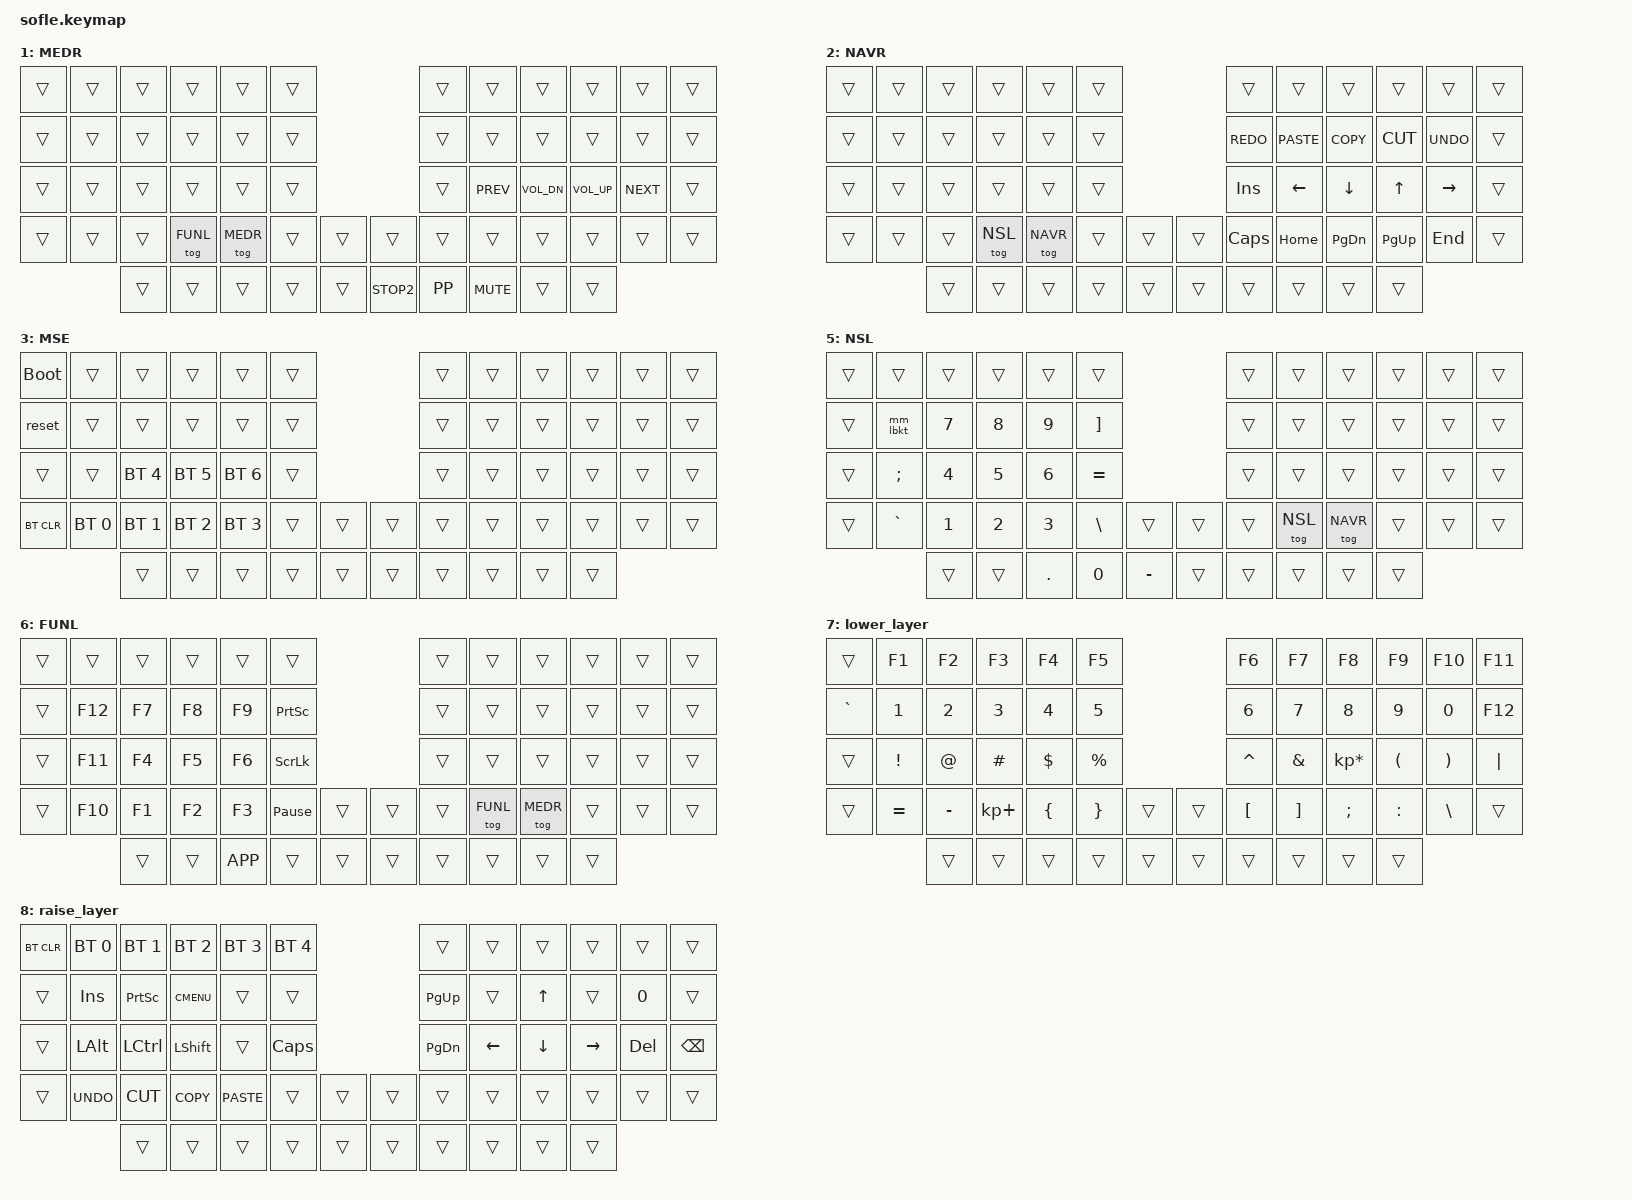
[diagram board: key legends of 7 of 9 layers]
/*
 * Copyright (c) 2020 The ZMK Contributors
 *
 * SPDX-License-Identifier: MIT
 * vim: filetype=dts:ts=4:sw=4:et
 */

#include <behaviors.dtsi>
#include <dt-bindings/zmk/keys.h>
#include <dt-bindings/zmk/bt.h>

#define MEDR 1
#define NAVR 2
#define MSE  3
#define NSSL 4
#define NSL  5
#define FUNL 6
// &mt LSHFT A

#define MACRO_COMBO(NAME, KEYPOS, LAYERS) \
  combo_##NAME { \
    bindings = <&m_##NAME>; \
    key-positions = <KEYPOS>; \
    layers = <LAYERS>; \
    timeout-ms = <50>; \
};

/ {
    #include "hd_combo_macros.dtsi"
    #include "linger.dtsi"

    behaviour {
        hm: homerow_mods {
            compatible = "zmk,behavior-hold-tap";
            label = "HOMEROW_MODS";
            #binding-cells = <2>;
            tapping-term-ms = <175>;
            quick-tap-ms = <125>;
            global-quick-tap;
            flavor = "tap-preferred";
            bindings = <&kp>, <&kp>;
        };
    };

    keymap {
        compatible = "zmk,keymap";

        default_layer {
//    ----------------------------------------------------------------------------------------------
//  0 |  `  |  1  |  2  |  3  |  4  |  5  |  5               6 |  6  |  7  |  8  |  9  |  0  |     | 11
// 12 | ESC |  Q  |  W  |  F  |  P  |  B  | 17              18 |  J  |  L  |  U  |  Y  |  '  |BKSPC| 23
// 24 | TAB |  A  |  R  |  S  |  T  |  G  | 29              30 |  M  |  N  |  E  |  I  |  O  |  '  | 35
// 36 |SHIFT|  Z  |  X  |  C  |  D  |  V  | MUTE| 42  43 |     |  K  |  H  |  ,  |  .  |  /  |SHIFT| 49
//             50 | GUI | ALT | CTRL|LOWER|ENTER| 54  55 |SPACE|RAISE| CTRL| ALT | GUI | 59
            bindings = <
&kp GRAVE &kp N1      &kp N2      &kp N3      &kp N4      &kp N5                      &kp N6 &kp N7      &kp N8      &kp N9      &kp N0      &none
&kp ESC   &qu Q &m_qu &kp W       &kp F       &kp P       &kp B                       &kp J  &kp L       &kp U       &kp Y       &kp APOS    &kp BSPC
&kp TAB   &hm LALT A  &hm LGUI R  &hm LSHFT S &hm LCTRL T &kp G                       &kp M  &hm RCTRL N &hm RSHFT E &hm RGUI I  &hm LALT O  &kp SQT
&kp LSHFT &kp Z       &kp X       &kp C       &kp D       &kp V  &kp C_MUTE &none     &kp K  &kp H       &mm_comma   &mm_dot     &kp FSLH    &kp RSHFT
                 &kp LGUI &kp LALT &lt MEDR ESC  &lt NAVR SPACE &lt MSE TAB    &lt NSSL RET  &lt NSL BSPC &lt FUNL DEL  &kp RALT  &kp RGUI
            >;

            sensor-bindings = <&inc_dec_kp C_VOL_UP C_VOL_DN &inc_dec_kp PG_UP PG_DN>;
        };

        MEDR {
            bindings = <
&trans &trans &trans &trans    &trans    &trans                    &trans   &trans     &trans       &trans       &trans     &trans
&trans &trans &trans &trans    &trans    &trans                    &trans   &trans     &trans       &trans       &trans     &trans
&trans &trans &trans &trans    &trans    &trans                    &trans   &kp K_PREV &kp K_VOL_DN &kp K_VOL_UP &kp K_NEXT &trans
&trans &trans &trans &tog FUNL &tog MEDR &trans &trans &trans      &trans   &trans     &trans       &trans       &trans     &trans
              &trans &trans    &trans    &trans &trans &kp K_STOP2 &kp K_PP &kp K_MUTE &trans       &trans
            >;
        };

        NAVR {
            bindings = <
&trans &trans &trans &trans   &trans    &trans               &trans     &trans      &trans     &trans    &trans     &trans
&trans &trans &trans &trans   &trans    &trans               &kp K_REDO &kp K_PASTE &kp K_COPY &kp K_CUT &kp K_UNDO &trans
&trans &trans &trans &trans   &trans    &trans               &kp INS    &kp LEFT    &kp DOWN   &kp UP    &kp RIGHT  &trans
&trans &trans &trans &tog NSL &tog NAVR &trans &trans &trans &kp CAPS   &kp HOME    &kp PG_DN  &kp PG_UP &kp END    &trans
              &trans &trans   &trans    &trans &trans &trans &trans     &trans      &trans     &trans
            >;
        };

        MSE {
            bindings = <
&bootloader &trans       &trans       &trans       &trans       &trans               &trans &trans &trans &trans &trans &trans
&reset      &trans       &trans       &trans       &trans       &trans               &trans &trans &trans &trans &trans &trans
&trans      &trans       &bt BT_SEL 4 &bt BT_SEL 5 &bt BT_SEL 6 &trans               &trans &trans &trans &trans &trans &trans
&bt BT_CLR  &bt BT_SEL 0 &bt BT_SEL 1 &bt BT_SEL 2 &bt BT_SEL 3 &trans &trans &trans &trans &trans &trans &trans &trans &trans
                        &trans        &trans      &trans        &trans &trans &trans &trans &trans &trans &trans
            >;
        };

        NSSL {
            bindings = <
&trans &trans    &trans   &trans    &trans          &trans                      &trans &trans    &trans &trans &trans &trans
&trans &kp LBRC  &kp AMPS &kp STAR  &kp NON_US_BSLH &kp RBRC                    &trans &trans    &trans &trans &trans &trans
&trans &kp COLON &kp DLLR &kp PRCNT &kp CARET        &kp PLUS                   &trans &trans    &trans &trans &trans &trans
&trans &kp TILDE &kp EXCL &kp AT    &kp HASH         &kp PIPE  &trans    &trans &trans &tog NSSL &trans &trans &trans &trans
                 &trans   &trans    &par &m_par LPAR &kp RPAR  &kp UNDER &trans &trans &trans &trans &trans
            >;
        };

        NSL {
            bindings = <
&trans &trans    &trans &trans &trans  &trans                     &trans &trans    &trans    &trans &trans &trans
&trans &mm_lbkt  &kp N7 &kp N8 &kp N9  &kp RBKT                   &trans &trans    &trans    &trans &trans &trans
&trans &kp SEMI  &kp N4 &kp N5 &kp N6  &kp EQUAL                  &trans &trans    &trans    &trans &trans &trans
&trans &kp GRAVE &kp N1 &kp N2 &kp N3  &kp BSLH  &trans    &trans &trans &tog NSL  &tog NAVR &trans &trans &trans
                 &trans &trans &kp DOT &kp N0    &kp MINUS &trans &trans &trans    &trans    &trans
            >;
        };

        FUNL {
            bindings = <
&trans &trans  &trans &trans &trans    &trans                        &trans &trans    &trans    &trans &trans &trans
&trans &kp F12 &kp F7 &kp F8 &kp F9    &kp PSCRN                     &trans &trans    &trans    &trans &trans &trans
&trans &kp F11 &kp F4 &kp F5 &kp F6    &kp SLCK                      &trans &trans    &trans    &trans &trans &trans
&trans &kp F10 &kp F1 &kp F2 &kp F3    &kp PAUSE_BREAK &trans &trans &trans &tog FUNL &tog MEDR &trans &trans &trans
               &trans &trans &kp K_APP &trans          &trans &trans &trans &trans    &trans    &trans
            >;
        };

        lower_layer {
// TODO: Some binds are waiting for shifted keycode support.
// ------------------------------------------------------------------------------------------------------------
// |       |  F1 |  F2 |  F3  |  F4  |  F5  |                   |  F6  |  F7   |  F8   |  F9  |  F10  |  F11  |
// | `     |   1 |   2 |   3  |   4  |   5  |                   |   6  |   7   |   8   |   9  |    0  |  F12  |
// |       |  !  |  @  |  #   |  $   |  %   |                   |  ^   |  &    |  *    |  (   |   )   |   |   |
// |       |  =  |  -  |  +   |  {   |  }   |        |  |       |  [   |  ]    |  ;    |  :   |   \   |       |
//               |     |      |      |      |        |  |       |      |       |       |      |
            bindings = <
&trans    &kp F1    &kp F2    &kp F3      &kp F4    &kp F5                    &kp F6    &kp F7   &kp F8          &kp F9    &kp F10   &kp F11
&kp GRAVE &kp N1    &kp N2    &kp N3      &kp N4    &kp N5                    &kp N6    &kp N7   &kp N8          &kp N9    &kp N0    &kp F12
&trans    &kp EXCL  &kp AT    &kp HASH    &kp DLLR  &kp PRCNT                 &kp CARET &kp AMPS &kp KP_MULTIPLY &kp LPAR  &kp RPAR  &kp PIPE
&trans    &kp EQUAL &kp MINUS &kp KP_PLUS &kp LBRC  &kp RBRC  &trans   &trans &kp LBKT  &kp RBKT &kp SEMI        &kp COLON &kp BSLH  &trans
                    &trans    &trans      &trans    &trans    &trans   &trans &trans    &trans   &trans          &trans
            >;

            sensor-bindings = <&inc_dec_kp C_VOL_UP C_VOL_DN &inc_dec_kp PG_UP PG_DN>;
        };

        raise_layer {
// ------------------------------------------------------------------------------------------------------------
// |BTCLR| BT1  | BT2  |  BT3  |  BT4  |  BT5 |                |      |      |       |      |       |       |
// |     | INS  | PSCR | GUI   |       |      |                | PGUP |      |   ^   |      |       |       |
// |     | ALT  | CTRL | SHIFT |       | CAPS |                | PGDN |   <- |   v   |  ->  |  DEL  | BKSPC |
// |     | UNDO | CUT  | COPY  | PASTE |      |      |  |      |      |      |       |      |       |       |
//              |      |       |       |      |      |  |      |      |      |       |      |
            bindings = <
&bt BT_CLR &bt BT_SEL 0 &bt BT_SEL 1 &bt BT_SEL 2 &bt BT_SEL 3 &bt BT_SEL 4             &trans    &trans    &trans   &trans    &trans  &trans
&trans     &kp INS      &kp PSCRN    &kp K_CMENU  &trans       &trans                   &kp PG_UP &trans    &kp UP   &trans    &kp N0  &trans
&trans     &kp LALT     &kp LCTRL    &kp LSHFT    &trans       &kp CLCK                 &kp PG_DN &kp LEFT  &kp DOWN &kp RIGHT &kp DEL &kp BSPC
&trans     &kp K_UNDO   &kp K_CUT    &kp K_COPY   &kp K_PASTE  &trans  &trans   &trans  &trans    &trans    &trans   &trans    &trans  &trans
                        &trans       &trans       &trans       &trans  &trans   &trans  &trans    &trans    &trans   &trans
            >;

            sensor-bindings = <&inc_dec_kp C_VOL_UP C_VOL_DN &inc_dec_kp PG_UP PG_DN>;
        };
    };

    combos {
        compatible = "zmk,combos";

        MACRO_COMBO(im, 33 30, 0) // "I'm "
        MACRO_COMBO(id, 33 40, 0) // "I'd "
        MACRO_COMBO(ill, 33 19, 0) // "I'll "
        MACRO_COMBO(ive, 33 41, 0) // "I've "
        MACRO_COMBO(wed, 14 40, 0) // "we'd "
        MACRO_COMBO(well, 14 19, 0) // "we'll "
        MACRO_COMBO(weve, 14 41, 0) // "we've "
        MACRO_COMBO(were, 14 26, 0) // "we're "
        MACRO_COMBO(youd, 21 40, 0) // "you'd "
        MACRO_COMBO(youll, 21 19, 0) // "you'll "
        MACRO_COMBO(youve, 21 41, 0) // "you've "
        MACRO_COMBO(youre, 21 26, 0) // "you're "
    };
};
